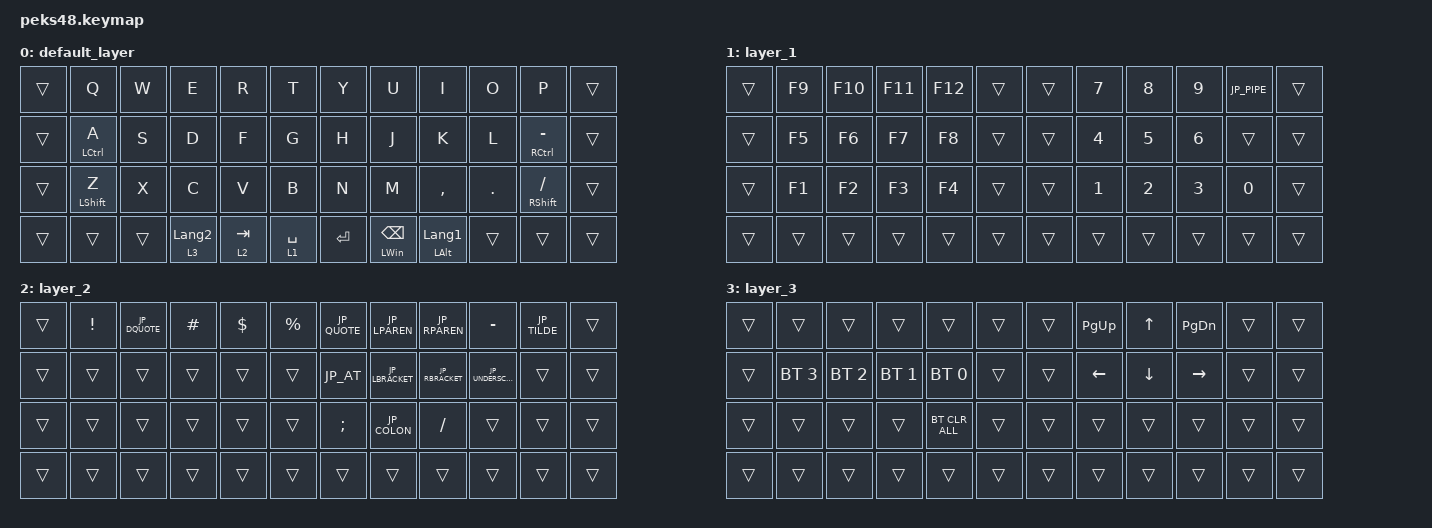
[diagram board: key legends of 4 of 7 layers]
#include <input/processors.dtsi>
#include <dt-bindings/zmk/input_transform.h>
#include <zephyr/dt-bindings/input/input-event-codes.h>
#include <behaviors.dtsi>
#include <dt-bindings/zmk/bt.h>
#include <dt-bindings/zmk/keys.h>
#include <dt-bindings/zmk/pointing.h>

// Conversion definition for using Japanese keyboard with OS settings

#define JP_DQUOTE       AT                // "
#define JP_AMPERSAND    CARET             // &
#define JP_QUOTE        AMPERSAND         // '
#define JP_EQUAL        UNDER             // =
#define JP_CARET        EQUAL             // ^
#define JP_YEN          0x89              // ¥
#define JP_PLUS         COLON             // +
#define JP_TILDE        PLUS              // ~
#define JP_PIPE         LS(0x89)          // |
#define JP_AT           LEFT_BRACKET      // @
#define JP_COLON        SINGLE_QUOTE      // :
#define JP_ASTERISK     DOUBLE_QUOTES     // *
#define JP_BACKQUOTE    LEFT_BRACE        // `
#define JP_UNDERSCORE   LS(0x87)          // _
#define JP_LBRACKET     RIGHT_BRACKET     // [
#define JP_RBRACKET     BACKSLASH         // ]
#define JP_LPAREN       ASTERISK          // (
#define JP_RPAREN       LEFT_PARENTHESIS  // )
#define JP_LBRACE       RIGHT_BRACE       // {
#define JP_RBRACE       PIPE              // }
#define JP_KANA         LANGUAGE_1        // かな
#define JP_EISU         LANGUAGE_2        // 英数
#define JP_HANZEN       GRAVE             // 半角/全角

&mt {
    flavor = "balanced";
    quick-tap-ms = <0>;
};

/ {
    keymap {
        compatible = "zmk,keymap";

        default_layer {
            bindings = <
&trans  &kp Q             &kp W   &kp E             &kp R      &kp T          &kp Y      &kp U                   &kp I                    &kp O    &kp P                  &trans
&trans  &mt LCTRL A       &kp S   &kp D             &kp F      &kp G          &kp H      &kp J                   &kp K                    &kp L    &mt RCTRL MINUS        &trans
&trans  &mt LEFT_SHIFT Z  &kp X   &kp C             &kp V      &kp B          &kp N      &kp M                   &kp COMMA                &kp DOT  &mt RIGHT_SHIFT SLASH  &trans
&trans  &trans            &trans  &lt 3 LANGUAGE_2  &lt 2 TAB  &lt 1 SPACE    &kp ENTER  &mt LEFT_WIN BACKSPACE  &mt LEFT_ALT LANGUAGE_1  &trans   &trans                 &trans
            >;
        };

        layer_1 {
            bindings = <
&trans  &kp F9  &kp F10  &kp F11  &kp F12  &trans    &trans  &kp NUMBER_7  &kp NUMBER_8  &kp NUMBER_9  &kp JP_PIPE   &trans
&trans  &kp F5  &kp F6   &kp F7   &kp F8   &trans    &trans  &kp NUMBER_4  &kp NUMBER_5  &kp NUMBER_6  &trans        &trans
&trans  &kp F1  &kp F2   &kp F3   &kp F4   &trans    &trans  &kp NUMBER_1  &kp NUMBER_2  &kp NUMBER_3  &kp NUMBER_0  &trans
&trans  &trans  &trans   &trans   &trans   &trans    &trans  &trans        &trans        &trans        &trans        &trans
            >;
        };

        layer_2 {
            bindings = <
&trans  &kp EXCLAMATION  &kp JP_DQUOTE  &kp POUND  &kp DOLLAR  &kp PERCENT    &kp JP_QUOTE   &kp JP_LPAREN    &kp JP_RPAREN      &kp MINUS          &kp JP_TILDE  &trans
&trans  &trans           &trans         &trans     &trans      &trans         &kp JP_AT      &kp JP_LBRACKET  &kp JP_RBRACKET    &kp JP_UNDERSCORE  &trans        &trans
&trans  &trans           &trans         &trans     &trans      &trans         &kp SEMICOLON  &kp JP_COLON     &kp SLASH          &trans             &trans        &trans
&trans  &trans           &trans         &trans     &trans      &trans         &trans         &trans           &trans             &trans             &trans        &trans
            >;
        };

        layer_3 {
            bindings = <
&trans  &trans        &trans        &trans        &trans          &trans    &trans  &kp PAGE_UP     &kp UP_ARROW    &kp PAGE_DOWN    &trans  &trans
&trans  &bt BT_SEL 3  &bt BT_SEL 2  &bt BT_SEL 1  &bt BT_SEL 0    &trans    &trans  &kp LEFT_ARROW  &kp DOWN_ARROW  &kp RIGHT_ARROW  &trans  &trans
&trans  &trans        &trans        &trans        &bt BT_CLR_ALL  &trans    &trans  &trans          &trans          &trans           &trans  &trans
&trans  &trans        &trans        &trans        &trans          &trans    &trans  &trans          &trans          &trans           &trans  &trans
            >;
        };

        layer_4 {
            bindings = <
&trans  &trans  &trans  &trans  &trans  &trans    &trans       &bt BT_SEL 0  &bt BT_SEL 1  &bt BT_SEL 2  &bt BT_SEL 3  &bt BT_SEL 4
&trans  &trans  &trans  &trans  &trans  &trans    &trans       &tog 6        &trans        &trans        &trans        &bt BT_CLR
&trans  &trans  &trans  &trans  &trans  &trans    &bootloader  &trans        &trans        &trans        &trans        &bt BT_CLR_ALL
&trans  &trans  &trans  &trans
            >;
        };

        layer_5 {
            bindings = <
&trans  &trans  &trans    &trans    &trans    &trans    &trans  &trans    &trans    &trans    &trans  &trans
&trans  &trans  &mkp MB3  &mkp MB2  &mkp MB1  &trans    &trans  &mkp MB1  &mkp MB2  &mkp MB3  &trans  &trans
&trans  &trans  &trans    &trans    &trans    &trans    &trans  &trans    &trans    &trans    &trans  &trans
&trans  &trans  &trans    &trans
            >;
        };

        layer_6 {
            bindings = <
&trans  &trans  &trans  &trans  &trans  &trans    &trans  &trans  &trans    &trans    &trans    &trans
&trans  &trans  &trans  &trans  &trans  &trans    &trans  &trans  &mkp MB1  &mkp MB3  &mkp MB2  &trans
&trans  &trans  &trans  &trans  &trans  &trans    &trans  &trans  &trans    &trans    &trans    &trans
&trans  &trans  &trans  &trans
            >;
        };
    };
};
